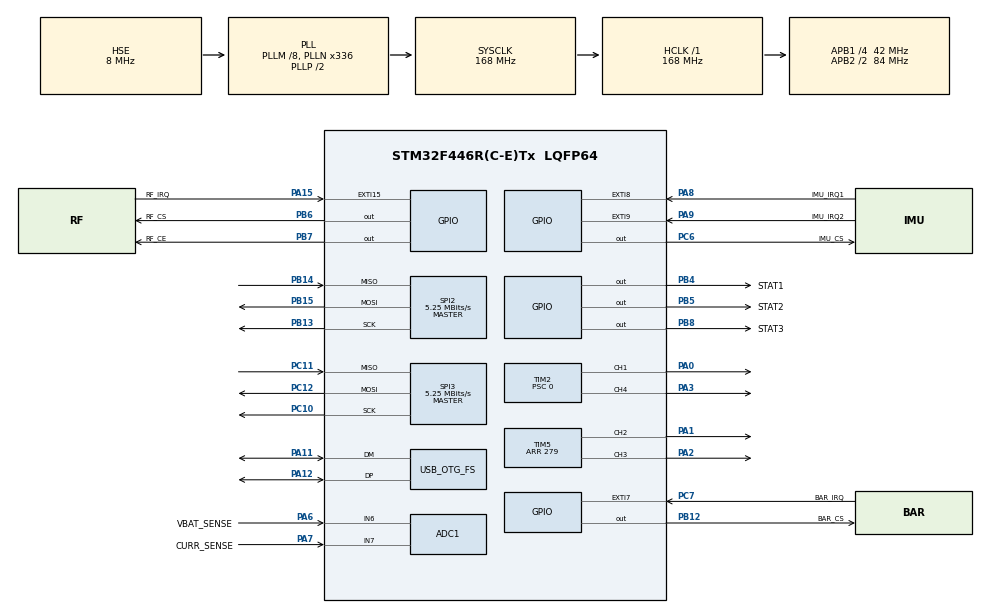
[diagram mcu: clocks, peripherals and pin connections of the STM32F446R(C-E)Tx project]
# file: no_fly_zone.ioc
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ADC1.Channel-1\#ChannelRegularConversion=ADC_CHANNEL_6
ADC1.Channel-2\#ChannelRegularConversion=ADC_CHANNEL_7
ADC1.DMAContinuousRequests=ENABLE
ADC1.ExternalTrigConv=ADC_EXTERNALTRIGCONV_T3_TRGO
ADC1.NbrOfConversion=2
ADC1.NbrOfConversionFlag=1
ADC1.Rank-1\#ChannelRegularConversion=1
ADC1.Rank-2\#ChannelRegularConversion=2
ADC1.SamplingTime-1\#ChannelRegularConversion=ADC_SAMPLETIME_144CYCLES
ADC1.SamplingTime-2\#ChannelRegularConversion=ADC_SAMPLETIME_144CYCLES
ADC1.master=1
Dma.ADC1.4.Direction=DMA_PERIPH_TO_MEMORY
Dma.ADC1.4.FIFOMode=DMA_FIFOMODE_DISABLE
Dma.ADC1.4.Instance=DMA2_Stream0
Dma.ADC1.4.MemDataAlignment=DMA_MDATAALIGN_HALFWORD
Dma.ADC1.4.MemInc=DMA_MINC_ENABLE
Dma.ADC1.4.Mode=DMA_CIRCULAR
Dma.ADC1.4.PeriphDataAlignment=DMA_PDATAALIGN_HALFWORD
Dma.ADC1.4.PeriphInc=DMA_PINC_DISABLE
Dma.ADC1.4.Priority=DMA_PRIORITY_LOW
Dma.Request0=TIM2_UP/CH4
Dma.Request1=TIM2_CH1
Dma.Request2=TIM5_CH2
Dma.Request3=TIM5_CH3/UP
Dma.Request4=ADC1
Dma.TIM2_CH1.1.Direction=DMA_MEMORY_TO_PERIPH
Dma.TIM2_CH1.1.FIFOMode=DMA_FIFOMODE_DISABLE
Dma.TIM2_CH1.1.Instance=DMA1_Stream5
Dma.TIM2_CH1.1.MemDataAlignment=DMA_MDATAALIGN_WORD
Dma.TIM2_CH1.1.MemInc=DMA_MINC_ENABLE
Dma.TIM2_CH1.1.Mode=DMA_CIRCULAR
Dma.TIM2_CH1.1.PeriphDataAlignment=DMA_PDATAALIGN_WORD
Dma.TIM2_CH1.1.PeriphInc=DMA_PINC_DISABLE
Dma.TIM2_CH1.1.Priority=DMA_PRIORITY_MEDIUM
Dma.TIM2_UP/CH4.0.Direction=DMA_MEMORY_TO_PERIPH
Dma.TIM2_UP/CH4.0.FIFOMode=DMA_FIFOMODE_DISABLE
Dma.TIM2_UP/CH4.0.Instance=DMA1_Stream7
Dma.TIM2_UP/CH4.0.MemDataAlignment=DMA_MDATAALIGN_WORD
Dma.TIM2_UP/CH4.0.MemInc=DMA_MINC_ENABLE
Dma.TIM2_UP/CH4.0.Mode=DMA_CIRCULAR
Dma.TIM2_UP/CH4.0.PeriphDataAlignment=DMA_PDATAALIGN_WORD
Dma.TIM2_UP/CH4.0.PeriphInc=DMA_PINC_DISABLE
Dma.TIM2_UP/CH4.0.Priority=DMA_PRIORITY_MEDIUM
Dma.TIM5_CH2.2.Direction=DMA_MEMORY_TO_PERIPH
Dma.TIM5_CH2.2.FIFOMode=DMA_FIFOMODE_DISABLE
Dma.TIM5_CH2.2.Instance=DMA1_Stream4
Dma.TIM5_CH2.2.MemDataAlignment=DMA_MDATAALIGN_WORD
Dma.TIM5_CH2.2.MemInc=DMA_MINC_ENABLE
Dma.TIM5_CH2.2.Mode=DMA_CIRCULAR
Dma.TIM5_CH2.2.PeriphDataAlignment=DMA_PDATAALIGN_WORD
Dma.TIM5_CH2.2.PeriphInc=DMA_PINC_DISABLE
Dma.TIM5_CH2.2.Priority=DMA_PRIORITY_MEDIUM
Dma.TIM5_CH3/UP.3.Direction=DMA_MEMORY_TO_PERIPH
Dma.TIM5_CH3/UP.3.FIFOMode=DMA_FIFOMODE_DISABLE
Dma.TIM5_CH3/UP.3.Instance=DMA1_Stream0
Dma.TIM5_CH3/UP.3.MemDataAlignment=DMA_MDATAALIGN_WORD
Dma.TIM5_CH3/UP.3.MemInc=DMA_MINC_ENABLE
Dma.TIM5_CH3/UP.3.Mode=DMA_CIRCULAR
Dma.TIM5_CH3/UP.3.PeriphDataAlignment=DMA_PDATAALIGN_WORD
Dma.TIM5_CH3/UP.3.PeriphInc=DMA_PINC_DISABLE
Dma.TIM5_CH3/UP.3.Priority=DMA_PRIORITY_MEDIUM
IWDG.Reload=3999
Mcu.Family=STM32F4
Mcu.Name=STM32F446R(C-E)Tx
Mcu.Package=LQFP64
NVIC.DMA1_Stream0_IRQn=true\:0\:0\:false\:false\:true\:false\:true\:true
NVIC.DMA1_Stream4_IRQn=true\:0\:0\:false\:false\:true\:false\:true\:true
NVIC.DMA1_Stream5_IRQn=true\:0\:0\:false\:false\:true\:false\:true\:true
NVIC.DMA1_Stream7_IRQn=true\:0\:0\:false\:false\:true\:false\:true\:true
NVIC.DMA2_Stream0_IRQn=true\:0\:0\:false\:false\:true\:false\:true\:true
NVIC.EXTI15_10_IRQn=true\:0\:0\:false\:false\:true\:true\:true\:true
NVIC.EXTI9_5_IRQn=true\:0\:0\:false\:false\:true\:true\:true\:true
NVIC.OTG_FS_IRQn=true\:0\:0\:false\:false\:true\:false\:true\:true
NVIC.PriorityGroup=NVIC_PRIORITYGROUP_4
PA0-WKUP.Signal=S_TIM2_CH1_ETR
PA1.Signal=S_TIM5_CH2
PA11.Mode=Device_Only
PA11.Signal=USB_OTG_FS_DM
PA12.Mode=Device_Only
PA12.Signal=USB_OTG_FS_DP
PA13.Mode=Trace_Asynchronous_SW
PA13.Signal=SYS_JTMS-SWDIO
PA14.Mode=Trace_Asynchronous_SW
PA14.Signal=SYS_JTCK-SWCLK
PA15.GPIO_Label=RF_IRQ
PA15.GPIO_ModeDefaultEXTI=GPIO_MODE_IT_FALLING
PA15.Signal=GPXTI15
PA2.Signal=S_TIM5_CH3
PA3.Signal=S_TIM2_CH4
PA6.GPIO_Label=VBAT_SENSE
PA6.Signal=ADCx_IN6
PA7.GPIO_Label=CURR_SENSE
PA7.Signal=ADCx_IN7
PA8.GPIO_Label=IMU_IRQ1
PA8.Signal=GPXTI8
PA9.GPIO_Label=IMU_IRQ2
PA9.Signal=GPXTI9
PB12.GPIO_Label=BAR_CS
PB12.Signal=GPIO_Output
PB13.Mode=Full_Duplex_Master
PB13.Signal=SPI2_SCK
PB14.Mode=Full_Duplex_Master
PB14.Signal=SPI2_MISO
PB15.Mode=Full_Duplex_Master
PB15.Signal=SPI2_MOSI
PB3.Mode=Trace_Asynchronous_SW
PB3.Signal=SYS_JTDO-SWO
PB4.GPIO_Label=STAT1
PB4.Signal=GPIO_Output
PB5.GPIO_Label=STAT2
PB5.Signal=GPIO_Output
PB6.GPIO_Label=RF_CS
PB6.Signal=GPIO_Output
PB7.GPIO_Label=RF_CE
PB7.Signal=GPIO_Output
PB8.GPIO_Label=STAT3
PB8.Signal=GPIO_Output
PC10.Mode=Full_Duplex_Master
PC10.Signal=SPI3_SCK
PC11.Mode=Full_Duplex_Master
PC11.Signal=SPI3_MISO
PC12.Mode=Full_Duplex_Master
PC12.Signal=SPI3_MOSI
PC6.GPIO_Label=IMU_CS
PC6.Signal=GPIO_Output
PC7.GPIO_Label=BAR_IRQ
PC7.Signal=GPXTI7
PH0-OSC_IN.Mode=HSE-External-Oscillator
PH0-OSC_IN.Signal=RCC_OSC_IN
PH1-OSC_OUT.Mode=HSE-External-Oscillator
PH1-OSC_OUT.Signal=RCC_OSC_OUT
ProjectManager.HeapSize=0x200
ProjectManager.StackSize=0x400
ProjectManager.TargetToolchain=Makefile
RCC.AHBFreq_Value=168000000
RCC.APB1CLKDivider=RCC_HCLK_DIV4
RCC.APB1Freq_Value=42000000
RCC.APB1TimFreq_Value=84000000
RCC.APB2CLKDivider=RCC_HCLK_DIV2
RCC.APB2Freq_Value=84000000
RCC.APB2TimFreq_Value=168000000
RCC.CortexFreq_Value=21000000
RCC.Cortex_Div=SYSTICK_CLKSOURCE_HCLK_DIV8
RCC.HCLKFreq_Value=168000000
RCC.HSE_VALUE=8000000
RCC.PLLI2SN=336
RCC.PLLM=8
RCC.PLLN=336
RCC.PLLQ=7
RCC.PLLSAIN=336
RCC.PLLSourceVirtual=RCC_PLLSOURCE_HSE
RCC.PWREXT_OverDrive=PWREXT_OverDrive_DESACTIVATED
RCC.PWR_Regulator_Voltage_Scale=PWR_REGULATOR_VOLTAGE_SCALE1
RCC.SYSCLKFreq_VALUE=168000000
RCC.SYSCLKSource=RCC_SYSCLKSOURCE_PLLCLK
RCC.USBFreq_Value=48000000
RCC.VCOOutputFreq_Value=336000000
SH.ADCx_IN6.0=ADC1_IN6,IN6
SH.ADCx_IN7.0=ADC1_IN7,IN7
SH.S_TIM2_CH1_ETR.0=TIM2_CH1,PWM Generation1 CH1
SH.S_TIM2_CH4.0=TIM2_CH4,PWM Generation4 CH4
SH.S_TIM5_CH2.0=TIM5_CH2,PWM Generation2 CH2
SH.S_TIM5_CH3.0=TIM5_CH3,PWM Generation3 CH3
SPI2.BaudRatePrescaler=SPI_BAUDRATEPRESCALER_8
SPI2.CalculateBaudRate=5.25 MBits/s
SPI2.Direction=SPI_DIRECTION_2LINES
SPI2.Mode=SPI_MODE_MASTER
SPI2.VirtualType=VM_MASTER
SPI3.BaudRatePrescaler=SPI_BAUDRATEPRESCALER_8
SPI3.CalculateBaudRate=5.25 MBits/s
SPI3.Direction=SPI_DIRECTION_2LINES
SPI3.Mode=SPI_MODE_MASTER
SPI3.VirtualType=VM_MASTER
TIM1.Prescaler=167
TIM1.TIM_MasterOutputTrigger=TIM_TRGO_UPDATE
TIM1.TIM_MasterSlaveMode=TIM_MASTERSLAVEMODE_ENABLE
TIM2.AutoReloadPreload=TIM_AUTORELOAD_PRELOAD_ENABLE
TIM2.Channel-PWM\ Generation1\ CH1=TIM_CHANNEL_1
TIM2.Channel-PWM\ Generation4\ CH4=TIM_CHANNEL_4
TIM2.OCPolarity_4=TIM_OCPOLARITY_HIGH
TIM2.Period=279
TIM2.Prescaler=0
TIM3.Period=2047
TIM3.Prescaler=8191
TIM3.TIM_MasterOutputTrigger=TIM_TRGO_UPDATE
TIM5.AutoReloadPreload=TIM_AUTORELOAD_PRELOAD_ENABLE
TIM5.Channel-PWM\ Generation2\ CH2=TIM_CHANNEL_2
TIM5.Channel-PWM\ Generation3\ CH3=TIM_CHANNEL_3
TIM5.OCPolarity_3=TIM_OCPOLARITY_HIGH
TIM5.Period=279
USB_DEVICE.CLASS_NAME_FS=CDC
USB_DEVICE.VirtualMode-CDC_FS=Cdc
USB_DEVICE.VirtualModeFS=Cdc_FS
USB_OTG_FS.VirtualMode=Device_Only
VP_IWDG_VS_IWDG.Mode=IWDG_Activate
VP_TIM1_VS_ClockSourceINT.Mode=Internal
VP_TIM2_VS_ClockSourceINT.Mode=Internal
VP_TIM3_VS_ClockSourceINT.Mode=Internal
VP_TIM4_VS_ClockSourceITR.Mode=TriggerSource_ITR0
VP_TIM4_VS_ControllerModeClock.Mode=Clock Mode
VP_USB_DEVICE_VS_USB_DEVICE_CDC_FS.Mode=CDC_FS
board=custom

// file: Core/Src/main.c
/* USER CODE BEGIN Header */
/**
  ******************************************************************************
  * @file           : main.c
  * @brief          : Main program body
  ******************************************************************************
  * @attention
  *
  * Copyright (c) 2026 STMicroelectronics.
  * All rights reserved.
  *
  * This software is licensed under terms that can be found in the LICENSE file
  * in the root directory of this software component.
  * If no LICENSE file comes with this software, it is provided AS-IS.
  *
  ******************************************************************************
  */
/* USER CODE END Header */
#include "main.h"
#include "usb_device.h"

/* USER CODE BEGIN Includes */
#include "app.h"
/* USER CODE END Includes */

ADC_HandleTypeDef hadc1;
DMA_HandleTypeDef hdma_adc1;

IWDG_HandleTypeDef hiwdg;

SPI_HandleTypeDef hspi2;
SPI_HandleTypeDef hspi3;

TIM_HandleTypeDef htim1;
TIM_HandleTypeDef htim2;
TIM_HandleTypeDef htim3;
TIM_HandleTypeDef htim4;
TIM_HandleTypeDef htim5;
DMA_HandleTypeDef hdma_tim2_up_ch4;
DMA_HandleTypeDef hdma_tim2_ch1;
DMA_HandleTypeDef hdma_tim5_ch2;
DMA_HandleTypeDef hdma_tim5_ch3_up;

void SystemClock_Config(void);
static void MX_GPIO_Init(void);
static void MX_DMA_Init(void);
static void MX_ADC1_Init(void);
static void MX_SPI2_Init(void);
static void MX_SPI3_Init(void);
static void MX_TIM2_Init(void);
static void MX_TIM5_Init(void);
static void MX_IWDG_Init(void);
static void MX_TIM3_Init(void);
static void MX_TIM1_Init(void);
static void MX_TIM4_Init(void);

int main(void)
{

    /* MCU Configuration--------------------------------------------------------*/

    /* Reset of all peripherals, Initializes the Flash interface and the Systick. */
    HAL_Init();

    /* Configure the system clock */
    SystemClock_Config();

    /* Initialize all configured peripherals */
    MX_GPIO_Init();
    MX_DMA_Init();
    MX_ADC1_Init();
    MX_SPI2_Init();
    MX_SPI3_Init();
    MX_TIM2_Init();
    MX_TIM5_Init();
    MX_USB_DEVICE_Init();
    //   MX_IWDG_Init();
    MX_TIM3_Init();
    MX_TIM1_Init();
    MX_TIM4_Init();
    /* USER CODE BEGIN 2 */
    app_init(&hadc1, &hspi2, &hspi3, &htim2, &htim3, &htim5, &htim1, &htim4, &hiwdg);
    /* USER CODE END 2 */

    /* Infinite loop */
    /* USER CODE BEGIN WHILE */
    while (1)
    {
        app();
        /* USER CODE END WHILE */

    }
}

void SystemClock_Config(void)
{
    RCC_OscInitTypeDef RCC_OscInitStruct = { 0 };
    RCC_ClkInitTypeDef RCC_ClkInitStruct = { 0 };

    /** Configure the main internal regulator output voltage
  */
    __HAL_RCC_PWR_CLK_ENABLE();
    __HAL_PWR_VOLTAGESCALING_CONFIG(PWR_REGULATOR_VOLTAGE_SCALE1);

    /** Initializes the RCC Oscillators according to the specified parameters
  * in the RCC_OscInitTypeDef structure.
  */
    RCC_OscInitStruct.OscillatorType = RCC_OSCILLATORTYPE_LSI | RCC_OSCILLATORTYPE_HSE;
    RCC_OscInitStruct.HSEState = RCC_HSE_ON;
    RCC_OscInitStruct.LSIState = RCC_LSI_ON;
    RCC_OscInitStruct.PLL.PLLState = RCC_PLL_ON;
    RCC_OscInitStruct.PLL.PLLSource = RCC_PLLSOURCE_HSE;
    RCC_OscInitStruct.PLL.PLLM = 8;
    RCC_OscInitStruct.PLL.PLLN = 336;
    RCC_OscInitStruct.PLL.PLLP = RCC_PLLP_DIV2;
    RCC_OscInitStruct.PLL.PLLQ = 7;
    RCC_OscInitStruct.PLL.PLLR = 2;
    if (HAL_RCC_OscConfig(&RCC_OscInitStruct) != HAL_OK)
    {
        Error_Handler();
    }

    /** Initializes the CPU, AHB and APB buses clocks
  */
    RCC_ClkInitStruct.ClockType = RCC_CLOCKTYPE_HCLK | RCC_CLOCKTYPE_SYSCLK | RCC_CLOCKTYPE_PCLK1 | RCC_CLOCKTYPE_PCLK2;
    RCC_ClkInitStruct.SYSCLKSource = RCC_SYSCLKSOURCE_PLLCLK;
    RCC_ClkInitStruct.AHBCLKDivider = RCC_SYSCLK_DIV1;
    RCC_ClkInitStruct.APB1CLKDivider = RCC_HCLK_DIV4;
    RCC_ClkInitStruct.APB2CLKDivider = RCC_HCLK_DIV2;

    if (HAL_RCC_ClockConfig(&RCC_ClkInitStruct, FLASH_LATENCY_5) != HAL_OK)
    {
        Error_Handler();
    }
}

static void MX_ADC1_Init(void)
{

    ADC_ChannelConfTypeDef sConfig = { 0 };

    /** Configure the global features of the ADC (Clock, Resolution, Data Alignment and number of conversion)
  */
    hadc1.Instance = ADC1;
    hadc1.Init.ClockPrescaler = ADC_CLOCK_SYNC_PCLK_DIV4;
    hadc1.Init.Resolution = ADC_RESOLUTION_12B;
    hadc1.Init.ScanConvMode = ENABLE;
    hadc1.Init.ContinuousConvMode = DISABLE;
    hadc1.Init.DiscontinuousConvMode = DISABLE;
    hadc1.Init.ExternalTrigConvEdge = ADC_EXTERNALTRIGCONVEDGE_RISING;
    hadc1.Init.ExternalTrigConv = ADC_EXTERNALTRIGCONV_T3_TRGO;
    hadc1.Init.DataAlign = ADC_DATAALIGN_RIGHT;
    hadc1.Init.NbrOfConversion = 2;
    hadc1.Init.DMAContinuousRequests = ENABLE;
    hadc1.Init.EOCSelection = ADC_EOC_SINGLE_CONV;
    if (HAL_ADC_Init(&hadc1) != HAL_OK)
    {
        Error_Handler();
    }

    /** Configure for the selected ADC regular channel its corresponding rank in the sequencer and its sample time.
  */
    sConfig.Channel = ADC_CHANNEL_6;
    sConfig.Rank = 1;
    sConfig.SamplingTime = ADC_SAMPLETIME_144CYCLES;
    if (HAL_ADC_ConfigChannel(&hadc1, &sConfig) != HAL_OK)
    {
        Error_Handler();
    }

    /** Configure for the selected ADC regular channel its corresponding rank in the sequencer and its sample time.
  */
    sConfig.Channel = ADC_CHANNEL_7;
    sConfig.Rank = 2;
    if (HAL_ADC_ConfigChannel(&hadc1, &sConfig) != HAL_OK)
    {
        Error_Handler();
    }
}

static void MX_IWDG_Init(void)
{

    hiwdg.Instance = IWDG;
    hiwdg.Init.Prescaler = IWDG_PRESCALER_4;
    hiwdg.Init.Reload = 3999;
    if (HAL_IWDG_Init(&hiwdg) != HAL_OK)
    {
        Error_Handler();
    }
}

static void MX_SPI2_Init(void)
{

    /* SPI2 parameter configuration*/
    hspi2.Instance = SPI2;
    hspi2.Init.Mode = SPI_MODE_MASTER;
    hspi2.Init.Direction = SPI_DIRECTION_2LINES;
    hspi2.Init.DataSize = SPI_DATASIZE_8BIT;
    hspi2.Init.CLKPolarity = SPI_POLARITY_LOW;
    hspi2.Init.CLKPhase = SPI_PHASE_1EDGE;
    hspi2.Init.NSS = SPI_NSS_SOFT;
    hspi2.Init.BaudRatePrescaler = SPI_BAUDRATEPRESCALER_8;
    hspi2.Init.FirstBit = SPI_FIRSTBIT_MSB;
    hspi2.Init.TIMode = SPI_TIMODE_DISABLE;
    hspi2.Init.CRCCalculation = SPI_CRCCALCULATION_DISABLE;
    hspi2.Init.CRCPolynomial = 10;
    if (HAL_SPI_Init(&hspi2) != HAL_OK)
    {
        Error_Handler();
    }
}

static void MX_SPI3_Init(void)
{

    /* SPI3 parameter configuration*/
    hspi3.Instance = SPI3;
    hspi3.Init.Mode = SPI_MODE_MASTER;
    hspi3.Init.Direction = SPI_DIRECTION_2LINES;
    hspi3.Init.DataSize = SPI_DATASIZE_8BIT;
    hspi3.Init.CLKPolarity = SPI_POLARITY_LOW;
    hspi3.Init.CLKPhase = SPI_PHASE_1EDGE;
    hspi3.Init.NSS = SPI_NSS_SOFT;
    hspi3.Init.BaudRatePrescaler = SPI_BAUDRATEPRESCALER_8;
    hspi3.Init.FirstBit = SPI_FIRSTBIT_MSB;
    hspi3.Init.TIMode = SPI_TIMODE_DISABLE;
    hspi3.Init.CRCCalculation = SPI_CRCCALCULATION_DISABLE;
    hspi3.Init.CRCPolynomial = 10;
    if (HAL_SPI_Init(&hspi3) != HAL_OK)
    {
        Error_Handler();
    }
}

static void MX_TIM1_Init(void)
{

    TIM_ClockConfigTypeDef sClockSourceConfig = { 0 };
    TIM_MasterConfigTypeDef sMasterConfig = { 0 };

    htim1.Instance = TIM1;
    htim1.Init.Prescaler = 167;
    htim1.Init.CounterMode = TIM_COUNTERMODE_UP;
    htim1.Init.Period = 65535;
    htim1.Init.ClockDivision = TIM_CLOCKDIVISION_DIV1;
    htim1.Init.RepetitionCounter = 0;
    htim1.Init.AutoReloadPreload = TIM_AUTORELOAD_PRELOAD_DISABLE;
    if (HAL_TIM_Base_Init(&htim1) != HAL_OK)
    {
        Error_Handler();
    }
    sClockSourceConfig.ClockSource = TIM_CLOCKSOURCE_INTERNAL;
    if (HAL_TIM_ConfigClockSource(&htim1, &sClockSourceConfig) != HAL_OK)
    {
        Error_Handler();
    }
    sMasterConfig.MasterOutputTrigger = TIM_TRGO_UPDATE;
    sMasterConfig.MasterSlaveMode = TIM_MASTERSLAVEMODE_ENABLE;
    if (HAL_TIMEx_MasterConfigSynchronization(&htim1, &sMasterConfig) != HAL_OK)
    {
        Error_Handler();
    }
}

static void MX_TIM2_Init(void)
{

    TIM_ClockConfigTypeDef sClockSourceConfig = { 0 };
    TIM_MasterConfigTypeDef sMasterConfig = { 0 };
    TIM_OC_InitTypeDef sConfigOC = { 0 };

    htim2.Instance = TIM2;
    htim2.Init.Prescaler = 0;
    htim2.Init.CounterMode = TIM_COUNTERMODE_UP;
    htim2.Init.Period = 279;
    htim2.Init.ClockDivision = TIM_CLOCKDIVISION_DIV1;
    htim2.Init.AutoReloadPreload = TIM_AUTORELOAD_PRELOAD_ENABLE;
    if (HAL_TIM_Base_Init(&htim2) != HAL_OK)
    {
        Error_Handler();
    }
    sClockSourceConfig.ClockSource = TIM_CLOCKSOURCE_INTERNAL;
    if (HAL_TIM_ConfigClockSource(&htim2, &sClockSourceConfig) != HAL_OK)
    {
        Error_Handler();
    }
    if (HAL_TIM_PWM_Init(&htim2) != HAL_OK)
    {
        Error_Handler();
    }
    sMasterConfig.MasterOutputTrigger = TIM_TRGO_RESET;
    sMasterConfig.MasterSlaveMode = TIM_MASTERSLAVEMODE_DISABLE;
    if (HAL_TIMEx_MasterConfigSynchronization(&htim2, &sMasterConfig) != HAL_OK)
    {
        Error_Handler();
    }
    sConfigOC.OCMode = TIM_OCMODE_PWM1;
    sConfigOC.Pulse = 0;
    sConfigOC.OCPolarity = TIM_OCPOLARITY_HIGH;
    sConfigOC.OCFastMode = TIM_OCFAST_DISABLE;
    if (HAL_TIM_PWM_ConfigChannel(&htim2, &sConfigOC, TIM_CHANNEL_1) != HAL_OK)
    {
        Error_Handler();
    }
    if (HAL_TIM_PWM_ConfigChannel(&htim2, &sConfigOC, TIM_CHANNEL_4) != HAL_OK)
    {
        Error_Handler();
    }
    HAL_TIM_MspPostInit(&htim2);
}

static void MX_TIM3_Init(void)
{

    TIM_ClockConfigTypeDef sClockSourceConfig = { 0 };
    TIM_MasterConfigTypeDef sMasterConfig = { 0 };

    htim3.Instance = TIM3;
    htim3.Init.Prescaler = 8191;
    htim3.Init.CounterMode = TIM_COUNTERMODE_UP;
    htim3.Init.Period = 2047;
    htim3.Init.ClockDivision = TIM_CLOCKDIVISION_DIV1;
    htim3.Init.AutoReloadPreload = TIM_AUTORELOAD_PRELOAD_DISABLE;
    if (HAL_TIM_Base_Init(&htim3) != HAL_OK)
    {
        Error_Handler();
    }
    sClockSourceConfig.ClockSource = TIM_CLOCKSOURCE_INTERNAL;
    if (HAL_TIM_ConfigClockSource(&htim3, &sClockSourceConfig) != HAL_OK)
    {
        Error_Handler();
    }
    sMasterConfig.MasterOutputTrigger = TIM_TRGO_UPDATE;
    sMasterConfig.MasterSlaveMode = TIM_MASTERSLAVEMODE_DISABLE;
    if (HAL_TIMEx_MasterConfigSynchronization(&htim3, &sMasterConfig) != HAL_OK)
    {
        Error_Handler();
    }
}

static void MX_TIM4_Init(void)
{

    TIM_SlaveConfigTypeDef sSlaveConfig = { 0 };
    TIM_MasterConfigTypeDef sMasterConfig = { 0 };

    htim4.Instance = TIM4;
    htim4.Init.Prescaler = 0;
    htim4.Init.CounterMode = TIM_COUNTERMODE_UP;
    htim4.Init.Period = 65535;
    htim4.Init.ClockDivision = TIM_CLOCKDIVISION_DIV1;
    htim4.Init.AutoReloadPreload = TIM_AUTORELOAD_PRELOAD_DISABLE;
    if (HAL_TIM_Base_Init(&htim4) != HAL_OK)
    {
        Error_Handler();
    }
    sSlaveConfig.SlaveMode = TIM_SLAVEMODE_EXTERNAL1;
    sSlaveConfig.InputTrigger = TIM_TS_ITR0;
    if (HAL_TIM_SlaveConfigSynchro(&htim4, &sSlaveConfig) != HAL_OK)
    {
        Error_Handler();
    }
    sMasterConfig.MasterOutputTrigger = TIM_TRGO_RESET;
    sMasterConfig.MasterSlaveMode = TIM_MASTERSLAVEMODE_DISABLE;
    if (HAL_TIMEx_MasterConfigSynchronization(&htim4, &sMasterConfig) != HAL_OK)
    {
        Error_Handler();
    }
}

static void MX_TIM5_Init(void)
{

    TIM_MasterConfigTypeDef sMasterConfig = { 0 };
    TIM_OC_InitTypeDef sConfigOC = { 0 };

    htim5.Instance = TIM5;
    htim5.Init.Prescaler = 0;
    htim5.Init.CounterMode = TIM_COUNTERMODE_UP;
    htim5.Init.Period = 279;
    htim5.Init.ClockDivision = TIM_CLOCKDIVISION_DIV1;
    htim5.Init.AutoReloadPreload = TIM_AUTORELOAD_PRELOAD_ENABLE;
    if (HAL_TIM_PWM_Init(&htim5) != HAL_OK)
    {
        Error_Handler();
    }
    sMasterConfig.MasterOutputTrigger = TIM_TRGO_RESET;
    sMasterConfig.MasterSlaveMode = TIM_MASTERSLAVEMODE_DISABLE;
    if (HAL_TIMEx_MasterConfigSynchronization(&htim5, &sMasterConfig) != HAL_OK)
    {
        Error_Handler();
    }
    sConfigOC.OCMode = TIM_OCMODE_PWM1;
    sConfigOC.Pulse = 0;
    sConfigOC.OCPolarity = TIM_OCPOLARITY_HIGH;
    sConfigOC.OCFastMode = TIM_OCFAST_DISABLE;
    if (HAL_TIM_PWM_ConfigChannel(&htim5, &sConfigOC, TIM_CHANNEL_2) != HAL_OK)
    {
        Error_Handler();
    }
    if (HAL_TIM_PWM_ConfigChannel(&htim5, &sConfigOC, TIM_CHANNEL_3) != HAL_OK)
    {
        Error_Handler();
    }
    HAL_TIM_MspPostInit(&htim5);
}

static void MX_DMA_Init(void)
{

    /* DMA controller clock enable */
    __HAL_RCC_DMA1_CLK_ENABLE();
    __HAL_RCC_DMA2_CLK_ENABLE();

    /* DMA interrupt init */
    /* DMA1_Stream0_IRQn interrupt configuration */
    HAL_NVIC_SetPriority(DMA1_Stream0_IRQn, 0, 0);
    HAL_NVIC_EnableIRQ(DMA1_Stream0_IRQn);
    /* DMA1_Stream4_IRQn interrupt configuration */
    HAL_NVIC_SetPriority(DMA1_Stream4_IRQn, 0, 0);
    HAL_NVIC_EnableIRQ(DMA1_Stream4_IRQn);
    /* DMA1_Stream5_IRQn interrupt configuration */
    HAL_NVIC_SetPriority(DMA1_Stream5_IRQn, 0, 0);
    HAL_NVIC_EnableIRQ(DMA1_Stream5_IRQn);
    /* DMA1_Stream7_IRQn interrupt configuration */
    HAL_NVIC_SetPriority(DMA1_Stream7_IRQn, 0, 0);
    HAL_NVIC_EnableIRQ(DMA1_Stream7_IRQn);
    /* DMA2_Stream0_IRQn interrupt configuration */
    HAL_NVIC_SetPriority(DMA2_Stream0_IRQn, 0, 0);
    HAL_NVIC_EnableIRQ(DMA2_Stream0_IRQn);
}

static void MX_GPIO_Init(void)
{
    GPIO_InitTypeDef GPIO_InitStruct = { 0 };

    /* GPIO Ports Clock Enable */
    __HAL_RCC_GPIOH_CLK_ENABLE();
    __HAL_RCC_GPIOA_CLK_ENABLE();
    __HAL_RCC_GPIOB_CLK_ENABLE();
    __HAL_RCC_GPIOC_CLK_ENABLE();

    /*Configure GPIO pin Output Level */
    HAL_GPIO_WritePin(GPIOB, BAR_CS_Pin | STAT1_Pin | STAT2_Pin | RF_CS_Pin | RF_CE_Pin | STAT3_Pin, GPIO_PIN_RESET);

    /*Configure GPIO pin Output Level */
    HAL_GPIO_WritePin(IMU_CS_GPIO_Port, IMU_CS_Pin, GPIO_PIN_RESET);

    /*Configure GPIO pins : BAR_CS_Pin STAT1_Pin STAT2_Pin RF_CS_Pin
                           RF_CE_Pin STAT3_Pin */
    GPIO_InitStruct.Pin = BAR_CS_Pin | STAT1_Pin | STAT2_Pin | RF_CS_Pin | RF_CE_Pin | STAT3_Pin;
    GPIO_InitStruct.Mode = GPIO_MODE_OUTPUT_PP;
    GPIO_InitStruct.Pull = GPIO_NOPULL;
    GPIO_InitStruct.Speed = GPIO_SPEED_FREQ_LOW;
    HAL_GPIO_Init(GPIOB, &GPIO_InitStruct);

    /*Configure GPIO pin : IMU_CS_Pin */
    GPIO_InitStruct.Pin = IMU_CS_Pin;
    GPIO_InitStruct.Mode = GPIO_MODE_OUTPUT_PP;
    GPIO_InitStruct.Pull = GPIO_NOPULL;
    GPIO_InitStruct.Speed = GPIO_SPEED_FREQ_LOW;
    HAL_GPIO_Init(IMU_CS_GPIO_Port, &GPIO_InitStruct);

    /*Configure GPIO pin : BAR_IRQ_Pin */
    GPIO_InitStruct.Pin = BAR_IRQ_Pin;
    GPIO_InitStruct.Mode = GPIO_MODE_IT_RISING;
    GPIO_InitStruct.Pull = GPIO_NOPULL;
    HAL_GPIO_Init(BAR_IRQ_GPIO_Port, &GPIO_InitStruct);

    /*Configure GPIO pins : IMU_IRQ1_Pin IMU_IRQ2_Pin */
    GPIO_InitStruct.Pin = IMU_IRQ1_Pin | IMU_IRQ2_Pin;
    GPIO_InitStruct.Mode = GPIO_MODE_IT_RISING;
    GPIO_InitStruct.Pull = GPIO_NOPULL;
    HAL_GPIO_Init(GPIOA, &GPIO_InitStruct);

    /*Configure GPIO pin : RF_IRQ_Pin */
    GPIO_InitStruct.Pin = RF_IRQ_Pin;
    GPIO_InitStruct.Mode = GPIO_MODE_IT_FALLING;
    GPIO_InitStruct.Pull = GPIO_NOPULL;
    HAL_GPIO_Init(RF_IRQ_GPIO_Port, &GPIO_InitStruct);

    /* EXTI interrupt init*/
    HAL_NVIC_SetPriority(EXTI9_5_IRQn, 0, 0);
    HAL_NVIC_EnableIRQ(EXTI9_5_IRQn);

    HAL_NVIC_SetPriority(EXTI15_10_IRQn, 0, 0);
    HAL_NVIC_EnableIRQ(EXTI15_10_IRQn);

}

void Error_Handler(void)
{
    __disable_irq();
    while (1)
    {
    }
}
